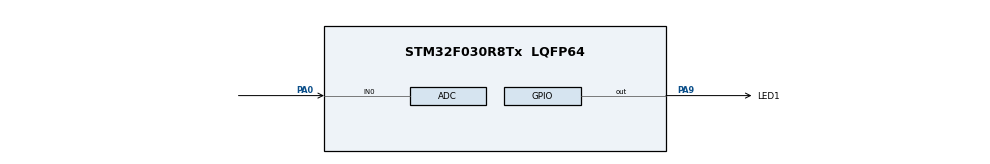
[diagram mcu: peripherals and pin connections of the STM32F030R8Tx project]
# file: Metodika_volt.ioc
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Mcu.Family=STM32F0
Mcu.Name=STM32F030R8Tx
Mcu.Package=LQFP64
PA0.Mode=IN0
PA0.Signal=ADC_IN0
PA9.GPIO_Label=LED1
PA9.Signal=GPIO_Output
ProjectManager.HeapSize=0x200
ProjectManager.StackSize=0x400
ProjectManager.TargetToolchain=STM32CubeIDE
board=custom

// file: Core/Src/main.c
/* USER CODE BEGIN Header */
/**
  ******************************************************************************
  * @file           : main.c
  * @brief          : Main program body
  ******************************************************************************
  * @attention
  *
  * Copyright (c) 2023 STMicroelectronics.
  * All rights reserved.
  *
  * This software is licensed under terms that can be found in the LICENSE file
  * in the root directory of this software component.
  * If no LICENSE file comes with this software, it is provided AS-IS.
  *
  ******************************************************************************
  */
/* USER CODE END Header */
#include "main.h"

ADC_HandleTypeDef hadc;

/* USER CODE BEGIN PV */
uint32_t adc_value;
/* USER CODE END PV */

void SystemClock_Config(void);
static void MX_GPIO_Init(void);
static void MX_ADC_Init(void);

int main(void)
{

  /* MCU Configuration--------------------------------------------------------*/

  /* Reset of all peripherals, Initializes the Flash interface and the Systick. */
  HAL_Init();

  /* Configure the system clock */
  SystemClock_Config();

  /* Initialize all configured peripherals */
  MX_GPIO_Init();
  MX_ADC_Init();

  /* Infinite loop */
  /* USER CODE BEGIN WHILE */
  while (1)
  {

	  HAL_ADC_Start(&hadc); // Запускаем АЦП
	  HAL_ADC_PollForConversion(&hadc, 10); // Ждем получение данных
	  adc_value = HAL_ADC_GetValue(&hadc); // Записываем данные в переменную "adc_value"
	  HAL_ADC_Stop(&hadc);// Останавливаем АЦП

	  HAL_Delay(10);// Задержка

	  if  (adc_value / 4095 == 1  ){ // Если полученно 5 вольт
		  HAL_GPIO_WritePin(LED1_GPIO_Port, LED1_Pin,GPIO_PIN_SET);// Загорается светодиод
	  }

	  else if (adc_value / 4036 == 1) { // Если 3,3 вольт
		  for(int i=0; i < 3; ++i){//* Цикл пока i меньше 3, будет мигать светодиод
			  HAL_GPIO_WritePin(LED1_GPIO_Port, LED1_Pin,GPIO_PIN_SET);
			  HAL_Delay(200);
			  HAL_GPIO_WritePin(LED1_GPIO_Port, LED1_Pin,GPIO_PIN_RESET);
			  HAL_Delay(500);
		  }
	  }
	  else { HAL_GPIO_WritePin(LED1_GPIO_Port, LED1_Pin,GPIO_PIN_RESET); } // Иначе светодиод не горит

	  HAL_Delay(10);// Задержка
    /* USER CODE END WHILE */

  }
}

void SystemClock_Config(void)
{
  RCC_OscInitTypeDef RCC_OscInitStruct = {0};
  RCC_ClkInitTypeDef RCC_ClkInitStruct = {0};

  /** Initializes the RCC Oscillators according to the specified parameters
  * in the RCC_OscInitTypeDef structure.
  */
  RCC_OscInitStruct.OscillatorType = RCC_OSCILLATORTYPE_HSI|RCC_OSCILLATORTYPE_HSI14;
  RCC_OscInitStruct.HSIState = RCC_HSI_ON;
  RCC_OscInitStruct.HSI14State = RCC_HSI14_ON;
  RCC_OscInitStruct.HSICalibrationValue = RCC_HSICALIBRATION_DEFAULT;
  RCC_OscInitStruct.HSI14CalibrationValue = 16;
  RCC_OscInitStruct.PLL.PLLState = RCC_PLL_NONE;
  if (HAL_RCC_OscConfig(&RCC_OscInitStruct) != HAL_OK)
  {
    Error_Handler();
  }

  /** Initializes the CPU, AHB and APB buses clocks
  */
  RCC_ClkInitStruct.ClockType = RCC_CLOCKTYPE_HCLK|RCC_CLOCKTYPE_SYSCLK
                              |RCC_CLOCKTYPE_PCLK1;
  RCC_ClkInitStruct.SYSCLKSource = RCC_SYSCLKSOURCE_HSI;
  RCC_ClkInitStruct.AHBCLKDivider = RCC_SYSCLK_DIV1;
  RCC_ClkInitStruct.APB1CLKDivider = RCC_HCLK_DIV1;

  if (HAL_RCC_ClockConfig(&RCC_ClkInitStruct, FLASH_LATENCY_0) != HAL_OK)
  {
    Error_Handler();
  }
}

static void MX_ADC_Init(void)
{

  ADC_ChannelConfTypeDef sConfig = {0};

  /** Configure the global features of the ADC (Clock, Resolution, Data Alignment and number of conversion)
  */
  hadc.Instance = ADC1;
  hadc.Init.ClockPrescaler = ADC_CLOCK_ASYNC_DIV1;
  hadc.Init.Resolution = ADC_RESOLUTION_12B;
  hadc.Init.DataAlign = ADC_DATAALIGN_RIGHT;
  hadc.Init.ScanConvMode = ADC_SCAN_DIRECTION_FORWARD;
  hadc.Init.EOCSelection = ADC_EOC_SINGLE_CONV;
  hadc.Init.LowPowerAutoWait = DISABLE;
  hadc.Init.LowPowerAutoPowerOff = DISABLE;
  hadc.Init.ContinuousConvMode = DISABLE;
  hadc.Init.DiscontinuousConvMode = DISABLE;
  hadc.Init.ExternalTrigConv = ADC_SOFTWARE_START;
  hadc.Init.ExternalTrigConvEdge = ADC_EXTERNALTRIGCONVEDGE_NONE;
  hadc.Init.DMAContinuousRequests = DISABLE;
  hadc.Init.Overrun = ADC_OVR_DATA_PRESERVED;
  if (HAL_ADC_Init(&hadc) != HAL_OK)
  {
    Error_Handler();
  }

  /** Configure for the selected ADC regular channel to be converted.
  */
  sConfig.Channel = ADC_CHANNEL_0;
  sConfig.Rank = ADC_RANK_CHANNEL_NUMBER;
  sConfig.SamplingTime = ADC_SAMPLETIME_1CYCLE_5;
  if (HAL_ADC_ConfigChannel(&hadc, &sConfig) != HAL_OK)
  {
    Error_Handler();
  }

}

static void MX_GPIO_Init(void)
{
  GPIO_InitTypeDef GPIO_InitStruct = {0};

  /* GPIO Ports Clock Enable */
  __HAL_RCC_GPIOA_CLK_ENABLE();

  /*Configure GPIO pin Output Level */
  HAL_GPIO_WritePin(LED1_GPIO_Port, LED1_Pin, GPIO_PIN_RESET);

  /*Configure GPIO pin : LED1_Pin */
  GPIO_InitStruct.Pin = LED1_Pin;
  GPIO_InitStruct.Mode = GPIO_MODE_OUTPUT_PP;
  GPIO_InitStruct.Pull = GPIO_NOPULL;
  GPIO_InitStruct.Speed = GPIO_SPEED_FREQ_LOW;
  HAL_GPIO_Init(LED1_GPIO_Port, &GPIO_InitStruct);

}

void Error_Handler(void)
{
  __disable_irq();
  while (1)
  {
  }
}
